# ATSAMRH707F18A register map
Vendor: Microchip Technology; Series: SAMRH707; File version: 0
CPU: CM7 r1p1, little endian, MPU, FPU, double-precision FPU, I-cache, D-cache, ITCM, DTCM, 3 interrupt priority bits, 69 interrupts
Registers are 32-bit, read-write, reset 0x0 unless marked. A register's access mark holds for its fields unless they carry their own. Offsets are from the block's base; [hi:lo] are bit positions.

## PCC — Parallel Capture Controller
Base 0x4001C000
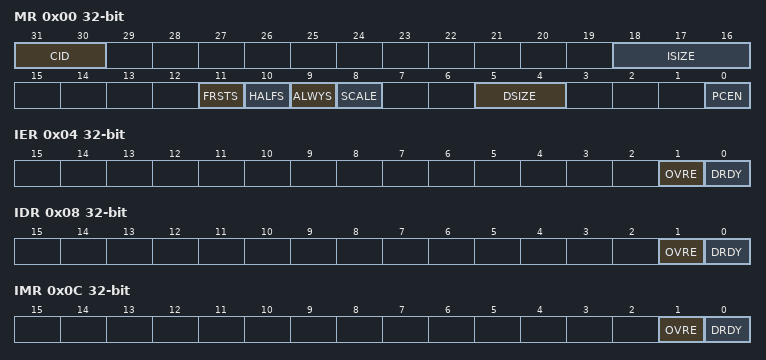
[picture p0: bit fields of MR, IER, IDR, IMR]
0x00 MR — Mode Register
  [31:30] CID — Clear If Disabled
    0=NONE (Clear not enabled); 1=DEN1 (Clear on falling edge on DEN1 enabled); 2=DEN2 (Clear on falling edge on DEN2 enabled); 3=EITHER (Clear on falling edge on either DEN1 or DEN2 enabled)
  [18:16] ISIZE — Input Data Size
    0=8_BITS (Input data bus size is 8 bits); 1=10_BITS (Input data bus size is 10 bits); 2=12_BITS (Input data bus size is 12 bits); 3=14_BITS (Input data bus size is 14 bits); 4=16_BITS (Input data bus size is 16 bits)
  [11] FRSTS — First Sample
  [10] HALFS — Half Sampling
  [9] ALWYS — Always Sampling
  [8] SCALE — Scale Data
  [5:4] DSIZE — Data Size
    0=1_DATA (1 data is read in the PCC_RHR); 1=2_DATA (2 data are read in the PCC_RHR); 2=4_DATA (4 data are read in the PCC_RHR (only for 8 bits data size, ISIZE = 0))
  [0] PCEN — Parallele Capture Enable
0x04 IER wo — Interrupt Enable Register
  [1] OVRE — Overrun Error Interrupt Enable
  [0] DRDY — Data Ready Interrupt Enable
0x08 IDR wo — Interrupt Disable Register
  [1] OVRE — Overrun Error Interrupt Disable
  [0] DRDY — Data Ready Interrupt Disable
0x0C IMR ro — Interrupt Mask Register
  [1] OVRE — Overrun Error Interrupt Mask
  [0] DRDY — Data Ready Interrupt Mask
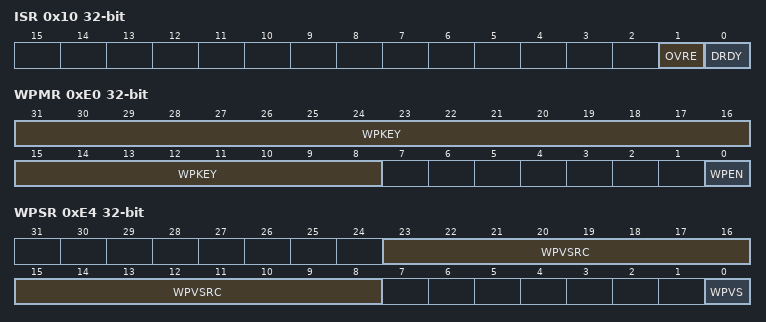
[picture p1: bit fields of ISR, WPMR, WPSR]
0x10 ISR ro — Interrupt Status Register
  [1] OVRE — Overrun Error.
  [0] DRDY — Data Ready
0x14 RHR ro — Reception Holding Register
  [31:0] RDATA — Reception Data.
0xE0 WPMR — Write Protection Mode Register
  [31:8] WPKEY — Write Protection Key.
    0x504343=PASSWD (Writing any other value in this field aborts the write operation of the WPEN bit. Always reads as 0.)
  [0] WPEN — Write Protection Enable
0xE4 WPSR ro — Write Protection Status Register
  [23:8] WPVSRC — Write Protection Violation Source
  [0] WPVS — Write Protection Violation Status

## RSTC — Reset Controller
Base 0x40100200
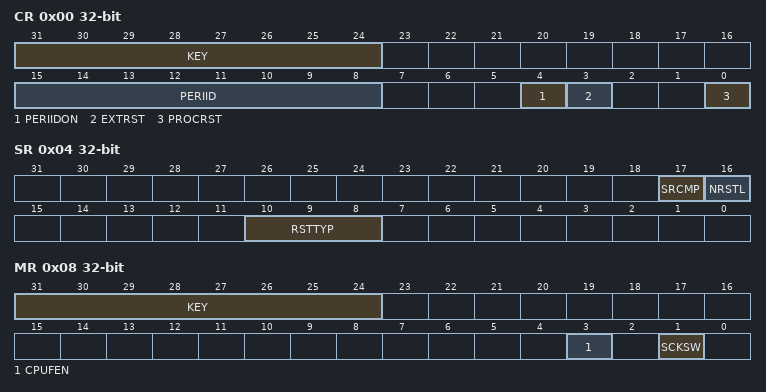
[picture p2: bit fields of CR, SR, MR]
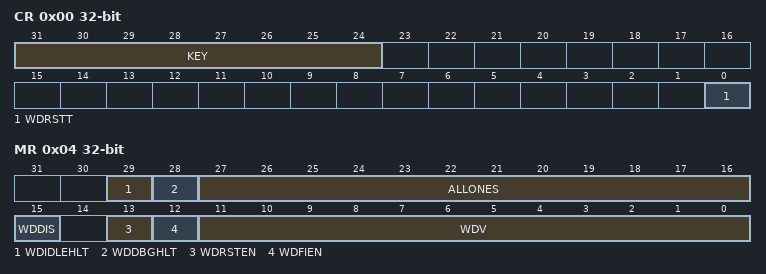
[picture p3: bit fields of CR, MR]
0x00 CR wo — Control Register
  [31:24] KEY — System Reset Key
    165=PASSWD (Writing any other value in this field aborts the write operation.)
  [15:8] PERIID — Peripheral Identifier
  [4] PERIIDON — External Reset
  [3] EXTRST — External Reset
  [0] PROCRST — Processor Reset
0x04 SR ro — Status Register
  [17] SRCMP — Software Reset Command in Progress
  [16] NRSTL — NRST Pin Level
  [10:8] RSTTYP — Reset Type
    0=GENERAL_RST (First powerup reset); 2=WDT_RST (Watchdog fault occurred); 3=SOFT_RST (Processor reset required by the software); 6=CPU_FAIL_RST (CPU clock failure detection occurred); 7=SLCK_XTAL_RST (32.768 kHz crystal failure detection fault occurred)
0x08 MR — Mode Register
  [31:24] KEY — Write Access Password
    165=PASSWD (Writing any other value in this field aborts the write operation. Always reads as 0.)
  [3] CPUFEN — CPU Fail Enable
  [1] SCKSW — Slow Clock Switching

## RSWDT — Reinforced Safety Watchdog Timer
Base 0x40100300
0x00 CR wo — Control Register
  [31:24] KEY — Password
    196=PASSWD (Writing any other value in this field aborts the write operation.)
  [0] WDRSTT — Watchdog Restart
0x04 MR — Mode Register
  [29] WDIDLEHLT — Watchdog Idle Halt
  [28] WDDBGHLT — Watchdog Debug Halt
  [27:16] ALLONES — Must Always Be Written with 0xFFF
  [15] WDDIS — Watchdog Disable
  [13] WDRSTEN — Watchdog Reset Enable
  [12] WDFIEN — Watchdog Fault Interrupt Enable
  [11:0] WDV — Watchdog Counter Value
0x08 SR ro — Status Register
  [0] WDUNF — Watchdog Underflow

## RTT — Real-time Timer
Base 0x40100230
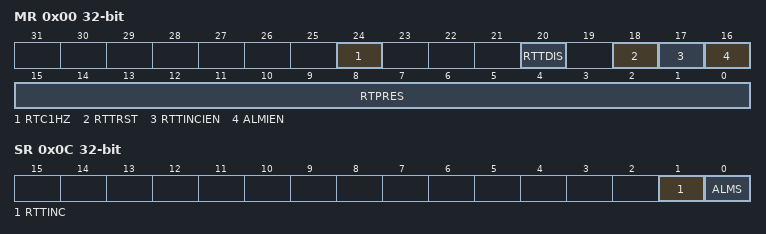
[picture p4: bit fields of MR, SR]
0x00 MR — Mode Register
  [24] RTC1HZ — Real-Time Clock 1Hz Clock Selection
  [20] RTTDIS — Real-time Timer Disable
  [18] RTTRST — Real-time Timer Restart
  [17] RTTINCIEN — Real-time Timer Increment Interrupt Enable
  [16] ALMIEN — Alarm Interrupt Enable
  [15:0] RTPRES — Real-time Timer Prescaler Value
0x04 AR — Alarm Register
  [31:0] ALMV — Alarm Value
0x08 VR ro — Value Register
  [31:0] CRTV — Current Real-time Value
0x0C SR ro — Status Register
  [1] RTTINC — Prescaler Roll-over Status (cleared on read)
  [0] ALMS — Real-time Alarm Status (cleared on read)
